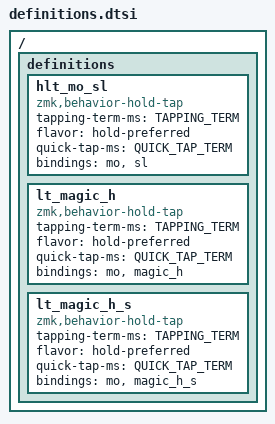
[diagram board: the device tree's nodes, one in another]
/ {
    definitions {
        TAPHOLD_TP_AGRESSIVE(arcane_repeat, &key_repeat, &arcane_key)

        TAPHOLD_TP(th_qexcl_morph, &qexcl_morph, &end_qexcl_morph)
        TAPHOLD_TP(th_dot_morph,   &dot_morph,   &end_dot_morph  )
        TAPHOLD_TP(th_comma_morph, &comma_morph, &end_comma_morph)

        TAPHOLD_TP(th_lpar, &end_lpar, &end_lpar)
        TAPHOLD_TP(th_rpar, &kp RPAR, &end_rpar)

        TAPHOLD_TP(th_lbkt, &kp LBKT, &end_lbkt)
        TAPHOLD_TP(th_rbkt, &kp RBKT, &end_rbkt)

        TAPHOLD_TP(th_lbrc, &kp LBRC, &end_lbrc)
        TAPHOLD_TP(th_rbrc, &kp RBRC, &end_rbrc)

        hlt_mo_sl: hlt_mo_sl {
            compatible = "zmk,behavior-hold-tap";
            #binding-cells = <2>;
            tapping-term-ms = <TAPPING_TERM>;
            flavor = "hold-preferred";
            quick-tap-ms = <QUICK_TAP_TERM>;
            bindings = <&mo>, <&sl>;
        };

        lt_magic_h: lt_magic_h {
            compatible = "zmk,behavior-hold-tap";
            #binding-cells = <2>;
            tapping-term-ms = <TAPPING_TERM>;
            flavor = "hold-preferred";
            quick-tap-ms = <QUICK_TAP_TERM>;
            bindings = <&mo>, <&magic_h>;
        };

        lt_magic_h_s: lt_magic_h_s {
            compatible = "zmk,behavior-hold-tap";
            #binding-cells = <2>;
            tapping-term-ms = <TAPPING_TERM>;
            flavor = "hold-preferred";
            quick-tap-ms = <QUICK_TAP_TERM>;
            bindings = <&mo>, <&magic_h_s>;
        };
    };
};

#define LT_NAV_ALPHA2   &hlt_mo_sl NAV ALPHA2
#define LT_NAV_SHIFTED2 &hlt_mo_sl NAV SHIFTED2

#define LT_MAGIC_H   &lt_magic_h   SHORTCUTS 0
#define LT_MAGIC_H_S &lt_magic_h_s SHORTCUTS 0
